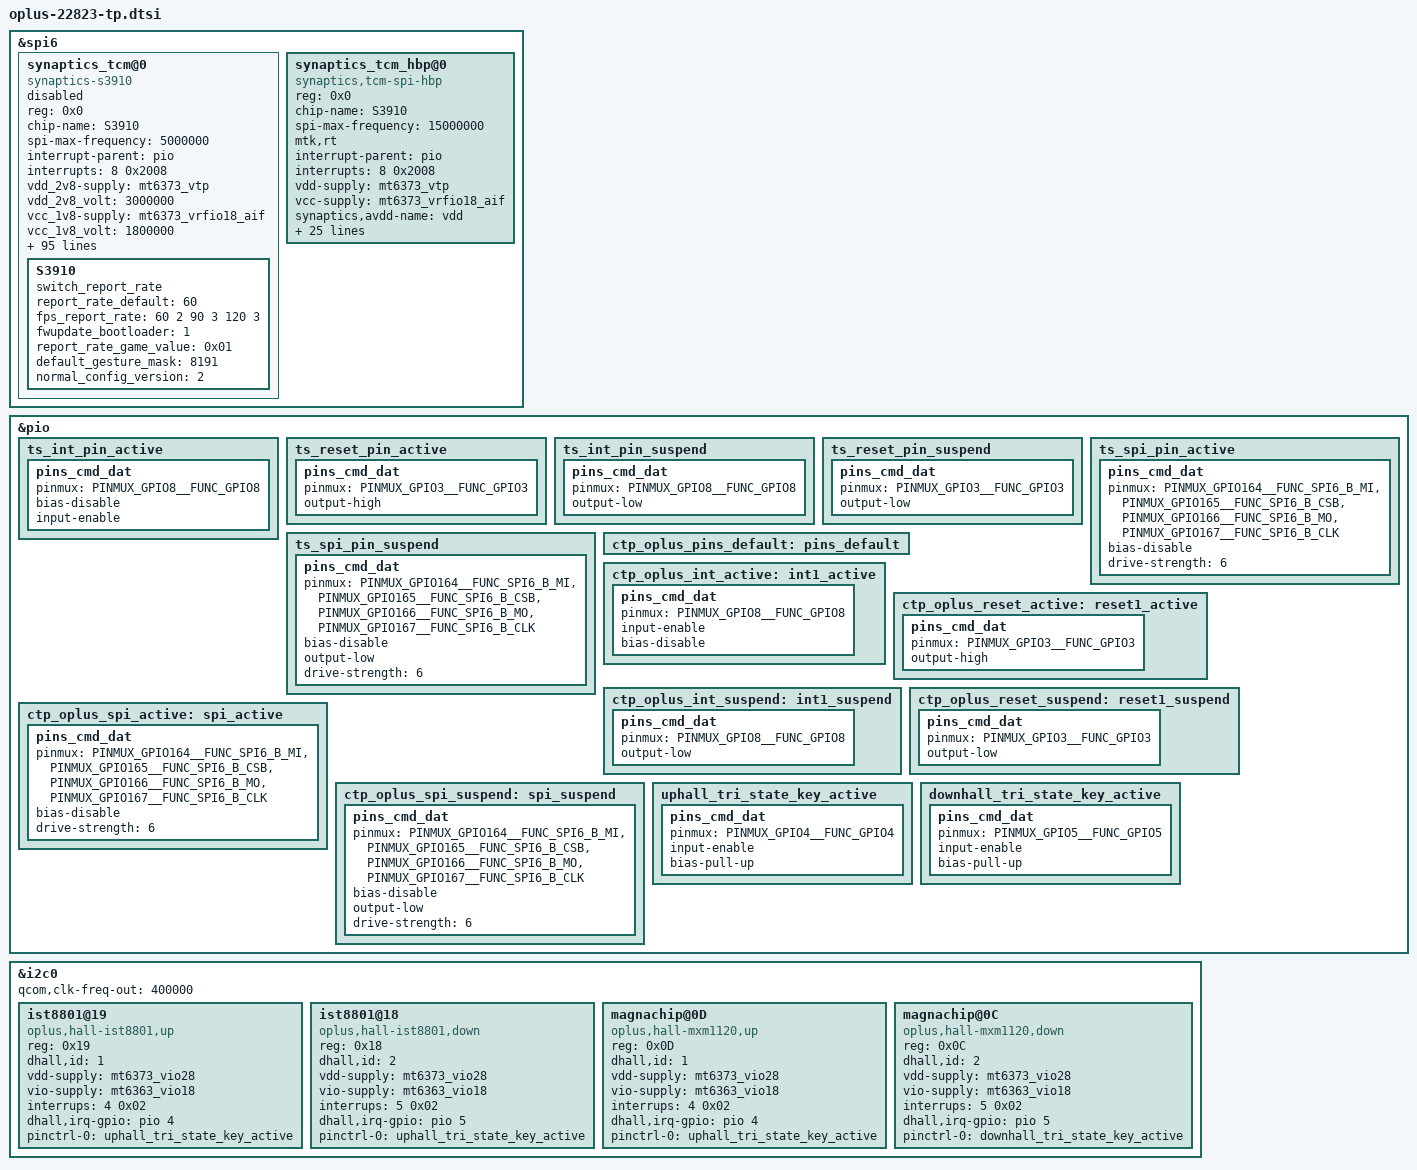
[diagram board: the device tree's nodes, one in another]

&spi6 {
	status = "okay";
	#address-cells = <1>;
	#size-cells = <0>;
	synaptics_tcm@0{
		compatible = "synaptics-s3910";
		reg = <0x0>;
		chip-name = "S3910";
		status = "disabled";
		spi-max-frequency = <5000000>;
		/* Interrupt && Irq-gpio */
		interrupt-parent = <&pio>;
		interrupts = <8 0x2008>;

		/* Power Config */
		vdd_2v8-supply  = <&mt6373_vtp>;
		vdd_2v8_volt = <3000000>;
		vcc_1v8-supply  = <&mt6373_vrfio18_aif>;
		vcc_1v8_volt = <1800000>;

		/* Other HW Resource */

		irq-gpio = <&pio 8 0x2008>;
		reset-gpio = <&pio 3 0x1>;
		//cs-gpio = <&pio 110 0x00>;
		//pinctrl-names = "default";
		//pinctrl-0 = <&ts_int_active &ts_reset_active>;

		pinctrl-names = "default",  "oplus_int_active",
		"oplus_reset_active", "oplus_int_suspend",
		"oplus_reset_suspend", "oplus_spi_active",
		"oplus_spi_suspend";
		pinctrl-0 = <&ctp_oplus_pins_default>;
		pinctrl-1 = <&ctp_oplus_int_active>;
		pinctrl-2 = <&ctp_oplus_reset_active>;
		pinctrl-3 = <&ctp_oplus_int_suspend>;
		pinctrl-4 = <&ctp_oplus_reset_suspend>;
		pinctrl-5 = <&ctp_oplus_spi_active>;
		pinctrl-6 = <&ctp_oplus_spi_suspend>;

		touchpanel,max-num-support = <10>;
		touchpanel,tx-rx-num = <16 36>;
		earsense,tx-rx-num = <17 18>;
		touchpanel,panel-coords = <12400 27720>;
		touchpanel,display-coords = <1240 2772>;
		touchpanel,touchmajor-limit = <128 216>;
		touchpanel,elimination-range = <20 200 200>;
		touchpanel,int-mode = <1>; /*0: interrupt and disable, 1:interrupt and not disable*/
		touchpanel,smooth-level = <0 1 2 4 7 9>;
		touchpanel,smooth-level-charging = <0 2 4 7 8 9>;
		touchpanel,sensitive-level = <0 70 55 40 25 10>;
		touchpanel,single-optimized-time = <8>;
		touchpanel,high-frame-rate-time = <60>;

		vid_len = <2>;
		panel_type = <7>;
		firmware_name = "SS";
		platform_support_project = <22823 21871 21872>;
		platform_support_project_dir = <22823 22823 22823>;
		platform_support_project_commandline = "default_commandline","default_commandline","default_commandline";

		prevention,curved_screen_V2;
		prevention,grip_disable_level = <6>;
		prevention,updelay_time_ms = <30>;
		prevention,makeup_cnt_weight = <5 1 2 2 2>;
		prevention,large_corner_range = <1400 3400>;
		prevention,large_corner_judge_condition = <500 400 1300 6 6>;
		prevention,trx_reject_condition = <8 7 7>;
		prevention,trx_strict_reject_condition = <8 6 6>;
		prevention,large_judge_time_ms = <500 50 30>;
		prevention,large_exit_condition = <8 8 2>;
		prevention,single_channel_width = <320 320>;
		prevention,normal_tap_condition = <10 300>;
		prevention,long_edge_condition = <200 90 120 80>;
		prevention,long_strict_edge_condition = <160 60>;
		prevention,long_fingerhold_condition = <50 6 4 4>;
		prevention,short_edge_condition = <200 90 180 80>;
		prevention,short_strict_edge_condition = <160 60>;
		prevention,large_strict_exit_condition = <4 4>;
		prevention,top_corner_config = <150 500 480>;
		prevention,edge_swipe_config = <350 1300>;

		prevention,curved_screen_V4;
		prevention,long_eliminate_point_type = <2 12400 9240 300 27720 300 1>;
		prevention,long_fingerhold_condition2 = <650 2000 0 0>;
		prevention,top_corner_config2 =<3 80 600 1500 0>;
		prevention,hor_long_top_corner_config =<350 2270 0 0>;
		prevention,top_middle_config =<12400 1000 1000 0>;
		prevention,corner_eliminate_point_type =<0 1380 2280 1>;
		prevention,finger_hold_differ_size = <0 0 400 300>;
		prevention,finger_hold_max_rx_exit_distance = <5 350 2300>;
		prevention,max_rx_exit_distance = <0 5 150 350 2000>;
		prevention,dynamic_finger_hold_exit_distance = <1 350 2300 450>;

		/* SW Support Feature Control */
		sportify_aod_gesture_support;
		black_gesture_support;
		pressure_report_support;
		charger_pump_support;
		game_switch_support;
		smart_gesture_support;
		spi_port_support;
		fw_update_app_support;
		fingerprint_underscreen_support;
		freq_hop_simulate_support;
		report_flow_unlock_support;
		screenoff_fingerprint_info_support;
		irq_need_dev_resume_ok;
		enable_point_auto_change;
		report_rate_white_list_support;
		kernel_grip_support;
		//grip_no_driver_support;
		health_monitor_support;
		black_gesture_indep_support;
		algorithm_support;
		snr_read_support;
		exception_upload_support;
		/*
		 *Virtual Key Config:
		 *1:touchpanel,button-type: <virtualkey_type  supportted_button-map>
		 *virtualkey_type:
		 *Type 1: using board_properties
		 *Type 2: using same IC (button zone&& touch zone are seprate)
		 *Type 3: using diffrent IC (button zone&& touch zone are seprate)
		 *Type 4: No need of virtual key process
		 *supportted_button-map:select|menu|home|back
		 *
		 *2:touchpanel,button-map
		 *type (X1,Y1)(X2,Y2)(X3,Y3)(Width_X,Hight_Y)--Only when button-type is 0
		 */
		touchpanel,button-type = <4>;
		touchpanel.button-TRx = <0 0>;

		S3910 {
			switch_report_rate;
			report_rate_default = <60>;
			fps_report_rate = <60 2 90 3 120 3>;//1:360Hz 2:125Hz 3:240Hz
			fwupdate_bootloader = <1>;
			report_rate_game_value = <0x01>;
			default_gesture_mask = <8191>;
			normal_config_version = <2>;
		};
	};

	synaptics_tcm_hbp@0{
		compatible = "synaptics,tcm-spi-hbp";
		reg = <0x0>;
		chip-name = "S3910";
		status = "okay";
		spi-max-frequency = <15000000>;

		mtk,rt;

		/* Interrupt && Irq-gpio */
		interrupt-parent = <&pio>;
		interrupts = <8 0x2008>;

		/* Power Config */
		vdd-supply = <&mt6373_vtp>;
		vcc-supply = <&mt6373_vrfio18_aif>;
		synaptics,avdd-name = "vdd";
		synaptics,vdd-name = "vcc";

		pinctrl-names = "ts_int_active", "ts_int_suspend",
		"ts_reset_active", "ts_reset_suspend",
		"ts_spi_active", "ts_spi_suspend";
		pinctrl-0 = <&ts_int_pin_active>;
		pinctrl-1 = <&ts_int_pin_suspend>;
		pinctrl-2 = <&ts_reset_pin_active>;
		pinctrl-3 = <&ts_reset_pin_suspend>;
		pinctrl-4 = <&ts_spi_pin_active>;
		pinctrl-5 = <&ts_spi_pin_suspend>;

		vid_len = <2>;
		panel_type = <7>;
		firmware_name = "Hbp", "Hbp";
		platform_support_project = <22823 21871>;
		platform_support_project_dir = <22823 22823>;
		platform_support_project_commandline = "default_commandline","default_commandline";

		synaptics,power-on-state = <1>;
		synaptics,power-delay-ms = <200>;
		synaptics,irq-gpio = <&pio 8 0x2008>; /* IRQF_ONESHOT | IRQF_TRIGGER_LOW */
		synaptics,irq-on-state = <0>;
		synaptics,reset-gpio = <&pio 3 0x1>;
		synaptics,reset-on-state = <0>;
		synaptics,reset-active-ms = <10>;
		synaptics,reset-delay-ms = <80>;
		synaptics,spi-mode = <0>;
		synaptics,spi-byte-delay-us = <0>;
		synaptics,spi-block-delay-us = <0>;
	};

};

&pio {
	ts_int_pin_active: ts_int_pin_active {
		pins_cmd_dat {
			pinmux = <PINMUX_GPIO8__FUNC_GPIO8>;
			bias-disable;
			input-enable;
		};
	};
	ts_reset_pin_active: ts_reset_pin_active {
		pins_cmd_dat {
			pinmux = <PINMUX_GPIO3__FUNC_GPIO3>;
			output-high;
		};
	};
	ts_int_pin_suspend: ts_int_pin_suspend {
		pins_cmd_dat {
			pinmux = <PINMUX_GPIO8__FUNC_GPIO8>;
			output-low;
		};
	};
	ts_reset_pin_suspend: ts_reset_pin_suspend {
		pins_cmd_dat {
			pinmux = <PINMUX_GPIO3__FUNC_GPIO3>;
			output-low;
		};
	};
	ts_spi_pin_active: ts_spi_pin_active {
		pins_cmd_dat {
			pinmux = <PINMUX_GPIO164__FUNC_SPI6_B_MI>,
				<PINMUX_GPIO165__FUNC_SPI6_B_CSB>,
				<PINMUX_GPIO166__FUNC_SPI6_B_MO>,
				<PINMUX_GPIO167__FUNC_SPI6_B_CLK>;
			bias-disable;
			drive-strength = <6>;
		};
	};
	ts_spi_pin_suspend: ts_spi_pin_suspend {
		pins_cmd_dat {
			pinmux = <PINMUX_GPIO164__FUNC_SPI6_B_MI>,
				<PINMUX_GPIO165__FUNC_SPI6_B_CSB>,
				<PINMUX_GPIO166__FUNC_SPI6_B_MO>,
				<PINMUX_GPIO167__FUNC_SPI6_B_CLK>;
			bias-disable;
			output-low;
			drive-strength = <6>;
		};
	};
};

&pio {
	ctp_oplus_pins_default: pins_default {
	};
	ctp_oplus_int_active: int1_active {
		pins_cmd_dat {
			pinmux = <PINMUX_GPIO8__FUNC_GPIO8>;
			input-enable;
			bias-disable;
		};
	};
	ctp_oplus_reset_active: reset1_active {
		pins_cmd_dat {
			pinmux = <PINMUX_GPIO3__FUNC_GPIO3>;
			output-high;
		};
	};
	ctp_oplus_int_suspend: int1_suspend {
		pins_cmd_dat {
			pinmux = <PINMUX_GPIO8__FUNC_GPIO8>;
			output-low;
		};
	};
	ctp_oplus_reset_suspend: reset1_suspend {
		pins_cmd_dat {
			pinmux = <PINMUX_GPIO3__FUNC_GPIO3>;
			output-low;
		};
	};
	ctp_oplus_spi_active: spi_active {
		pins_cmd_dat {
			pinmux = <PINMUX_GPIO164__FUNC_SPI6_B_MI>,
				<PINMUX_GPIO165__FUNC_SPI6_B_CSB>,
				<PINMUX_GPIO166__FUNC_SPI6_B_MO>,
				<PINMUX_GPIO167__FUNC_SPI6_B_CLK>;
			bias-disable;
			drive-strength = <6>;
		};
	};
	ctp_oplus_spi_suspend: spi_suspend {
		pins_cmd_dat {
			pinmux = <PINMUX_GPIO164__FUNC_SPI6_B_MI>,
				<PINMUX_GPIO165__FUNC_SPI6_B_CSB>,
				<PINMUX_GPIO166__FUNC_SPI6_B_MO>,
				<PINMUX_GPIO167__FUNC_SPI6_B_CLK>;
			bias-disable;
			output-low;
			drive-strength = <6>;
		};
	};
};

&i2c0 {
        status = "ok";
        qcom,clk-freq-out = <400000>;
        ist8801@19 {
           compatible = "oplus,hall-ist8801,up";
           reg = <0x19>;
           dhall,id = <1>;
           vdd-supply = <&mt6373_vio28>;
           vio-supply = <&mt6363_vio18>;
           interrups = <4 0x02>;
           dhall,irq-gpio = <&pio 4 0x2008>;
           pinctrl-names = "uphall_tri_state_key_active";
           pinctrl-0 = <&uphall_tri_state_key_active>;
        };
        ist8801@18 {
            compatible = "oplus,hall-ist8801,down";
            reg = <0x18>;
            dhall,id = <2>;
            vdd-supply = <&mt6373_vio28>;
            vio-supply = <&mt6363_vio18>;
            interrups = <5 0x02>;
            dhall,irq-gpio = <&pio 5 0x2008>;
            pinctrl-names = "uphall_tri_state_key_active";
            pinctrl-0 = <&uphall_tri_state_key_active>;
    };
        magnachip@0D {
                compatible = "oplus,hall-mxm1120,up";
                reg = <0x0D>;
                dhall,id = <1>;
                vdd-supply = <&mt6373_vio28>;
                vio-supply = <&mt6363_vio18>;
                //interrupt-parent = <&tlmm>;
                interrups = <4 0x02>;
                dhall,irq-gpio = <&pio 4 0x2008>;
                pinctrl-names = "uphall_tri_state_key_active";
                pinctrl-0 = <&uphall_tri_state_key_active>;
        };
        magnachip@0C {
                compatible = "oplus,hall-mxm1120,down";
                reg = <0x0C>;
                dhall,id = <2>;
                vdd-supply = <&mt6373_vio28>;
                vio-supply = <&mt6363_vio18>;
                //interrupt-parent = <&tlmm>;
                interrups = <5 0x02>;
                dhall,irq-gpio = <&pio 5 0x2008>;
                pinctrl-names = "downhall_tri_state_key_active";
                pinctrl-0 = <&downhall_tri_state_key_active>;
        };
};

&pio {
    uphall_tri_state_key_active: uphall_tri_state_key_active {
                pins_cmd_dat {
                        pinmux = <PINMUX_GPIO4__FUNC_GPIO4>;
                        input-enable;
                        bias-pull-up;
                };
        };
    downhall_tri_state_key_active: downhall_tri_state_key_active {
                pins_cmd_dat {
                        pinmux = <PINMUX_GPIO5__FUNC_GPIO5>;
                        input-enable;
                        bias-pull-up;
                };
        };
};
